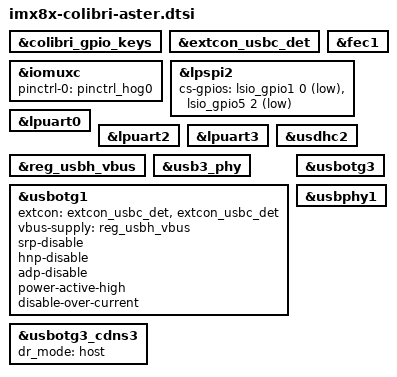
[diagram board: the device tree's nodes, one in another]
// SPDX-License-Identifier: GPL-2.0-or-later OR MIT
/*
 * Copyright 2018-2021 Toradex
 */

&colibri_gpio_keys {
	status = "okay";
};

&extcon_usbc_det {
	status = "okay";
};

/* Colibri Ethernet */
&fec1 {
	status = "okay";
};

&iomuxc {
	pinctrl-names = "default";
	pinctrl-0 = <&pinctrl_hog0>;
};

/* Colibri SPI */
&lpspi2 {
	cs-gpios = <&lsio_gpio1 0 GPIO_ACTIVE_LOW>,
		   <&lsio_gpio5 2 GPIO_ACTIVE_LOW>;
};

/* Colibri UART_B */
&lpuart0 {
	status = "okay";
};

/* Colibri UART_C */
&lpuart2 {
	status = "okay";
};

/* Colibri UART_A */
&lpuart3 {
	status= "okay";
};

&reg_usbh_vbus {
	status = "okay";
};

/* Colibri SDCard */
&usdhc2 {
	status = "okay";
};

/* USB PHY for &usbotg3 */
&usb3_phy {
	status = "okay";
};

&usbotg1 {
	extcon = <&extcon_usbc_det &extcon_usbc_det>;
	vbus-supply = <&reg_usbh_vbus>;
	srp-disable;
	hnp-disable;
	adp-disable;
	power-active-high;
	disable-over-current;
	status = "okay";
};

&usbotg3 {
	status = "okay";
};

&usbotg3_cdns3 {
	dr_mode = "host";
	status = "okay";
};

/* USB PHY for &usbotg1 */
&usbphy1 {
	status = "okay";
};
